# STM32MP13xx register map
File version: 1.5
CPU: CA7 r0p0, little endian, MPU, FPU, 4 interrupt priority bits
Registers are 32-bit, read-write, reset 0x0 unless marked. A register's access mark holds for its fields unless they carry their own. Offsets are from the block's base; [hi:lo] are bit positions; {n}, {i} and the like mark numbered series; 'fields as' and 'values as' point back to an identical list.

## ETH1 (part 4 of 4) — ETH
Base 0x5800A000
Same registers: ETH2 0x5800E000
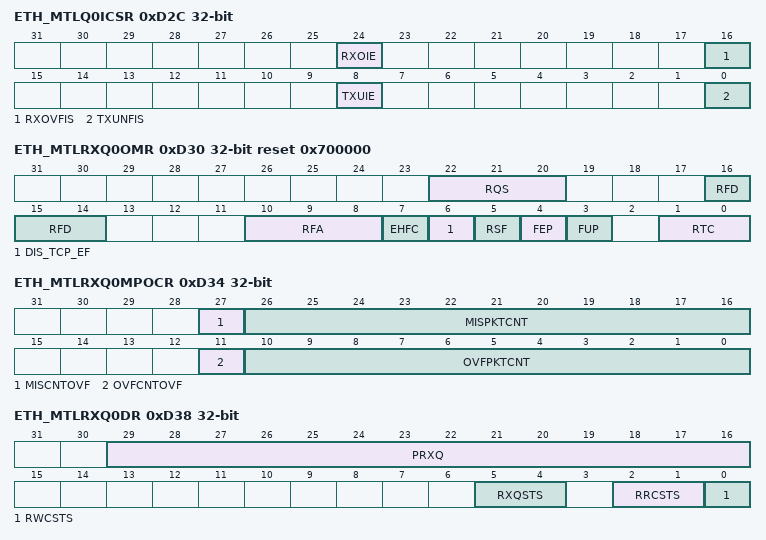
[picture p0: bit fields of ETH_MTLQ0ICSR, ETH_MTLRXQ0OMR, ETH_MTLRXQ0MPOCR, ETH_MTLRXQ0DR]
0xD2C ETH_MTLQ0ICSR — Queue 0 interrupt control status Register
  [24] RXOIE — Receive Queue Overflow Interrupt Enable When this bit is set, the Receive Queue Overflow interrupt is enabled. When this bit is reset, the Receive Queue Overflow interrupt is disabled.
  [16] RXOVFIS — Receive Queue Overflow Interrupt Status This bit indicates that the Receive Queue had an overflow while receiving the packet. If a partial packet is transferred to the application, the overflow status is set in RDES3[21]. This bit is cleared when the application writes 1 to this bit.
  [8] TXUIE — Transmit Queue Underflow Interrupt Enable When this bit is set, the Transmit Queue Underflow interrupt is enabled. When this bit is reset, the Transmit Queue Underflow interrupt is disabled.
  [0] TXUNFIS — Transmit Queue Underflow Interrupt Status This bit indicates that the Transmit Queue had an underflow while transmitting the packet. Transmission is suspended and an Underflow Error TDES3[2] is set. This bit is cleared when the application writes 1 to this bit.
0xD30 ETH_MTLRXQ0OMR access per field reset 0x700000 — Rx queue 0 operating mode register
  [22:20] RQS ro — Receive Queue Size This field indicates the size of the allocated Receive queues in blocks of 256 bytes. The RQS field is read-write only if the number of Rx queues more than one and the reset value is 0x0.
  [16:14] RFD rw — Threshold for Deactivating Flow Control (in half-duplex and full-duplex modes) These bits control the threshold (fill-level of Rx queue) at which the flow control is deasserted after activation: 2: Full minus 2 Kbytes, that is, FULL 2 Kbytes 3: Full minus 2.5 Kbytes, that is, FULL 2.5 Kbytes 4: Full minus 2.5 Kbytes, that is, FULL 3 Kbytes 5: Full minus 2.5 Kbytes, that is, FULL 3.5 Kbytes ... 6: Full minus 4 Kbytes, that is, FULL 4 Kbytes 7: Full minus 4.5 Kbytes, that is, FULL 4.5 Kbytes The deassertion is effective only after flow control is asserted. Note: The value must be programmed in such a way to make sure that the threshold is a positive number. When the EHFC is set high, these values are applicable only when the Rx queue size determined by the RQS field of this register, is equal to or greater than 4 Kbytes. For a given queue size, the values ranges between 0 and the encoding for FULL minus (QSIZE - 0.5 Kbyte) and all other values are illegal. Here the term FULL and QSIZE refers to the queue size determined by the RQS field of this register. The width of this field depends on RX FIFO size selected during the configuration. Remaining bits are reserved and read only. This field is reserved and read only when the RX FIFO size selected during configuration is less than 4Kbytes.
    0=Full minus 1 Kbyte, that is, FULL 1 Kbyte; 1=Full minus 1.5 Kbyte, that is, FULL 1.5 Kbyte
  [10:8] RFA rw — Threshold for Activating Flow Control (in half-duplex and full-duplex These bits control the threshold (fill-level of Rx queue) at which the flow control is activated: For more information on encoding for this field, see RFD.
  [7] EHFC rw — Enable Hardware Flow Control When this bit is set, the flow control signal operation, based on the fill-level of Rx queue, is enabled. When reset, the flow control operation is disabled. This bit is not used (reserved and always reset) when the Rx queue is less than 4 Kbytes.
  [6] DIS_TCP_EF rw — Disable Dropping of TCP/IP Checksum Error Packets When this bit is set, the MAC does not drop the packets which only have the errors detected by the Receive Checksum Offload engine. Such packets have errors only in the encapsulated payload. There are no errors (including FCS error) in the Ethernet packet received by the MAC. When this bit is reset, all error packets are dropped if the FEP bit is reset. This bit is reserved and RO when Enable Receive TCP/IP Checksum Check is not selected.
  [5] RSF rw — Receive Queue Store and Forward When this bit is set, the Ethernet peripheral reads a packet from the Rx queue only after the complete packet has been written to it, ignoring the RTC field of this register. When this bit is reset, the Rx queue operates in the Threshold (cut-through) mode, subject to the threshold specified by the RTC field of this register.
  [4] FEP rw — Forward Error Packets When this bit is reset, the Rx queue drops packets with error status (CRC error, receive error, watchdog timeout, or overflow). However, if the start byte (write) pointer of a packet is already transferred to the read controller side (in Threshold mode), the packet is not dropped. When this bit is set, all packets except the runt error packets are forwarded to the application or DMA. If the RSF bit is set and the Rx queue overflows when a partial packet is written, the packet is dropped irrespective of the setting of this bit. However, if the RSF bit is reset and the Rx queue overflows when a partial packet is written, a partial packet may be forwarded to the application or DMA.
  [3] FUP rw — Forward Undersized Good Packets When this bit is set, the Rx queue forwards the undersized good packets (packets with no error and length less than 64 bytes), including pad-bytes and CRC. When this bit is reset, the Rx queue drops all packets of less than 64 bytes, unless a packet is already transferred because of the lower value of Rx Threshold, for example, RTC = 01.
  [1:0] RTC rw — Receive Queue Threshold Control These bits control the threshold level of the MTL Rx queue (in bytes): The received packet is transferred to the application or DMA when the packet size within the MTL Rx queue is larger than the threshold. In addition, full packets with length less than the threshold are automatically transferred. This field is valid only when the RSF bit is zero. This field is ignored when the RSF bit is set to 1.
    0=64; 1=32; 2=96; 3=128
0xD34 ETH_MTLRXQ0MPOCR ro — Rx queue 0 missed packet and overflow counter register
  [27] MISCNTOVF — Missed Packet Counter Overflow Bit When set, this bit indicates that the Rx Queue Missed Packet Counter crossed the maximum limit.
  [26:16] MISPKTCNT — Missed Packet Counter This field indicates the number of packets missed by the Ethernet peripheral because the application asserted ari_pkt_flush_i[] for this queue. This counter is reset when this register is read. This counter is incremented by 1 when the DMA discards the packet because of buffer unavailability.
  [11] OVFCNTOVF — Overflow Counter Overflow Bit When set, this bit indicates that the Rx Queue Overflow Packet Counter field crossed the maximum limit.
  [10:0] OVFPKTCNT — Overflow Packet Counter This field indicates the number of packets discarded by the Ethernet peripheral because of Receive queue overflow. This counter is incremented each time the Ethernet peripheral discards an incoming packet because of overflow. This counter is reset when this register is read.
0xD38 ETH_MTLRXQ0DR ro — Rx queue 0 debug register
  [29:16] PRXQ — Number of Packets in Receive Queue This field indicates the current number of packets in the Rx queue. The theoretical maximum value for this field is 256Kbyte/16bytes = 16K Packets, that is, Max_Queue_Size/Min_Packet_Size.
  [5:4] RXQSTS — MTL Rx Queue Fill-Level Status This field gives the status of the fill-level of the Rx queue:
    0=Rx queue empty; 1=Rx queue fill-level below flow-control deactivate threshold; 2=Rx queue fill-level above flow-control activate threshold; 3=Rx queue full
  [2:1] RRCSTS — MTL Rx Queue Read Controller State This field gives the state of the Rx queue Read controller:
    0=Idle state; 1=Reading packet data; 2=Reading packet status (or timestamp); 3=Flushing the packet data and status
  [0] RWCSTS — MTL Rx Queue Write Controller Active Status When high, this bit indicates that the MTL Rx queue Write controller is active, and it is transferring a received packet to the Rx queue.
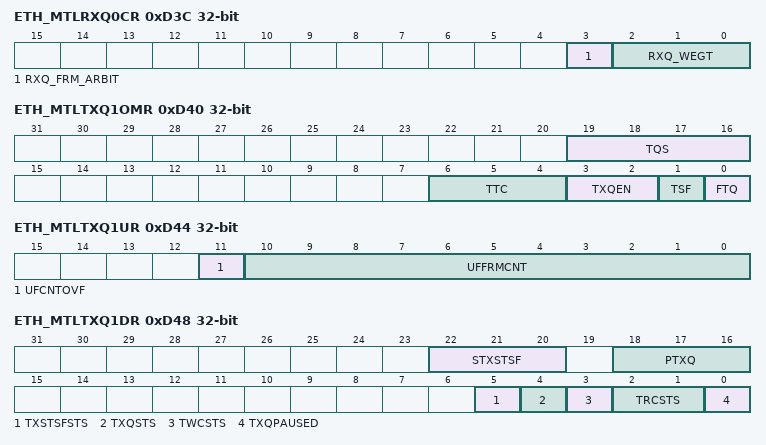
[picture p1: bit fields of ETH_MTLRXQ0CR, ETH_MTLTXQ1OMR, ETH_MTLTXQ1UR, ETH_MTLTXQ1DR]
0xD3C ETH_MTLRXQ0CR access per field — Rx queue 0 control register
  [3] RXQ_FRM_ARBIT ro — Receive Queue Packet Arbitration When this bit is set, the Ethernet peripheral drives the packet data to the ARI interface such that the entire packet data of currently-selected queue is transmitted before switching to other queue. When this bit is reset, the Ethernet peripheral drives the packet data to the ARI interface such that the following amount of data of currently-selected queue is transmitted before switching to other queue: PBL amount of data (indicated by ari_qN_pbl_i[]) or complete data of a packet The status and the timestamp are not a part of the PBL data. Therefore, the Ethernet peripheral drives the complete status (including timestamp status) during first PBL request for the packet (in store-and-forward mode) or the last PBL request for the packet (in Threshold mode).
  [2:0] RXQ_WEGT rw — Receive Queue Weight This field indicates the weight assigned to the Rx queue 0. The weight is used as the number of continuous PBL requests or contiguous packets (depending on the RXQ_PKT_ARBIT) allocated to the queue in one arbitration cycle.
0xD40 ETH_MTLTXQ1OMR — Tx queue 1 operating mode Register
  [19:16] TQS — Transmit queue size This field indicates the size of the allocated transmit queues in blocks of 256 bytes. Queue size range from 256 bytes (TQS=0b000) to 2048 bytes (TQS=0b111).
  [6:4] TTC — Transmit Threshold Control These bits control the threshold level of the MTL Tx queue. The transmission starts when the packet size within the MTL Tx queue is larger than the threshold. In addition, full packets with length less than the threshold are also transmitted. These bits are used only when the TSF bit is reset.
    0=32; 1=64; 2=96; 3=128; 4=192; 5=256; 6=384; 7=512
  [3:2] TXQEN — Transmit Queue Enable This field is used to enable/disable the transmit queue 0. Others: Reserved, must not be used. Note: In multiple Tx queues configuration, all the queues are disabled by default. Enable the Tx queue by programming this field.
    0=Not enabled; 2=Enabled
  [1] TSF — Transmit Store and Forward When this bit is set, the transmission starts when a full packet resides in the MTL Tx queue. When this bit is set, the TTC values specified in Bits[6:4] of this register are ignored. This bit should be changed only when the transmission is stopped.
  [0] FTQ — Flush Transmit Queue When this bit is set, the Tx queue controller logic is reset to its default values. Therefore, all the data in the Tx queue is lost or flushed. This bit is internally reset when the flushing operation is complete. Until this bit is reset, you should not write to the ETH_MTLTXQ1OMR register. The data which is already accepted by the MAC transmitter is not flushed. It is scheduled for transmission and results in underflow and runt packet transmission. Note: The flush operation is complete only when the Tx queue is empty and the application has accepted the pending Tx Status of all transmitted packets. To complete this flush operation, the PHY Tx clock (eth_mii_tx_clk) should be active.
0xD44 ETH_MTLTXQ1UR ro — Tx queue 1 underflow register
  [11] UFCNTOVF — Overflow Bit for Underflow Packet Counter This bit is set every time the Tx queue Underflow Packet Counter field overflows, that is, it has crossed the maximum count. In such a scenario, the overflow packet counter is reset to all-zeros and this bit indicates that the rollover happened.
  [10:0] UFFRMCNT — Underflow Packet Counter This field indicates the number of packets aborted by the controller because of Tx queue Underflow. This counter is incremented each time the MAC aborts outgoing packet because of underflow. The counter is cleared when this register is read.
0xD48 ETH_MTLTXQ1DR ro — Tx queue 1 debug Register
  [22:20] STXSTSF — Number of Status Words in Tx Status FIFO of Queue This field indicates the current number of status in the Tx Status FIFO of this queue. When the DTXSTS bit of ETH_MTLOMR register is set to 1, this field does not reflect the number of status words in Tx Status FIFO.
  [18:16] PTXQ — Number of Packets in the Transmit Queue This field indicates the current number of packets in the Tx queue. When the DTXSTS bit of ETH_MTLOMR register is set to 1, this field does not reflect the number of packets in the Transmit queue.
  [5] TXSTSFSTS — MTL Tx Status FIFO Full Status When high, this bit indicates that the MTL Tx Status FIFO is full. Therefore, the MTL cannot accept any more packets for transmission.
  [4] TXQSTS — MTL Tx Queue Not Empty Status When this bit is high, it indicates that the MTL Tx queue is not empty and some data is left for transmission.
  [3] TWCSTS — MTL Tx Queue Write Controller Status When high, this bit indicates that the MTL Tx queue Write Controller is active, and it is transferring the data to the Tx queue.
  [2:1] TRCSTS — MTL Tx Queue Read Controller Status This field indicates the state of the Tx Queue Read Controller:
    0=Idle state; 1=Read state (transferring data to the MAC transmitter); 2=Waiting for pending Tx Status from the MAC transmitter; 3=Flushing the Tx queue because of the Packet Abort request from the MAC
  [0] TXQPAUSED — Transmit Queue in Pause When this bit is high and the Rx flow control is enabled, it indicates that the Tx queue is in the Pause condition (in the full-duplex only mode) because of the following: Reception of the PFC packet for the priorities assigned to the Tx queue when PFC is enabled Reception of 802.3x Pause packet when PFC is disabled
0xD50 ETH_MTLTXQ1ECR — Tx queue 1 ETS control Register
  [3] CC — Credit Control When this bit is set, the accumulated credit parameter in the credit-based shaper algorithm logic is not reset to zero when there is positive credit and no packet to transmit in Channel 1. The credit accumulates even when there is no packet waiting in Channel 1 and another channel is transmitting. When this bit is reset, the accumulated credit parameter in the credit-based shaper algorithm logic is set to zero when there is positive credit and no packet to transmit in Channel 1. When there is no packet waiting in Channel 1 and other channel is transmitting, no credit is accumulated.
0xD54 ETH_MTLTXQ1ESR ro — Tx queue x ETS status Register
  [23:0] ABS — Average Bits per Slot This field contains the average transmitted bits per slot. When the DCB operation is enabled for Queue x, this field is computed over every 10 million bit times slot (10 ms in 1000 Mbps; 100 ms in 100 Mbps). The maximum value is 0x989680. This bit is reserved in configurations with only one transmit queue.
0xD58 ETH_MTLTXQ1QWR — Tx queue 1 quantum weight register
  [6:0] ISCQW — quantum weight If WRR algorithm is enabled for queue 1 generic traffic, this field contains the weight for this queue. The maximum value is 0x64.
0xD60 ETH_MTLTXQ1HCR — Tx Queue 1 hiCredit register
  [28:0] HC — hiCredit Value This field contains the hiCredit value required for the credit-based shaper algorithm. This is the maximum value that can be accumulated in the credit parameter. This is specified in bits scaled by 1 024. The maximum value is maxInterferenceSize, that is, best-effort maximum packet size (16 384 bytes or 131 072 bits). The value to be specified is 131 072 * 1 024 = 134 217 728 or 0x0800 0000.
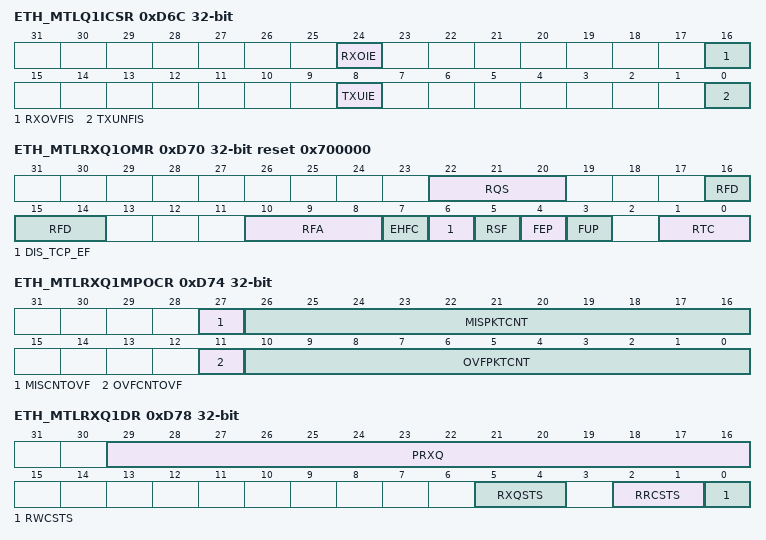
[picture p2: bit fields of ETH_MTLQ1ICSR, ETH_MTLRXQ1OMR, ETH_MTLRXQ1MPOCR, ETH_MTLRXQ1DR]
0xD6C ETH_MTLQ1ICSR — Queue 1 interrupt control status Register
  fields as ETH_MTLQ0ICSR
0xD70 ETH_MTLRXQ1OMR access per field reset 0x700000 — Rx queue 1 operating mode register
  fields as ETH_MTLRXQ0OMR
0xD74 ETH_MTLRXQ1MPOCR ro — Rx queue 1 missed packet and overflow counter register
  fields as ETH_MTLRXQ0MPOCR
0xD78 ETH_MTLRXQ1DR ro — Rx queue 1 debug register
  fields as ETH_MTLRXQ0DR
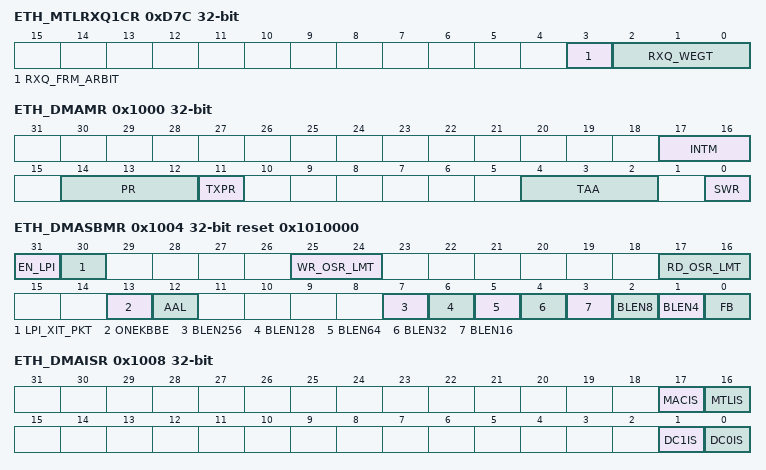
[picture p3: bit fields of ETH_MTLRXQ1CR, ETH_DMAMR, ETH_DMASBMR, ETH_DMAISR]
0xD7C ETH_MTLRXQ1CR access per field — Rx queue 1 control register
  fields as ETH_MTLRXQ0CR
0x1000 ETH_DMAMR access per field — DMA mode register
  [17:16] INTM rw — Interrupt Mode This field defines the interrupt mode of the Ethernet peripheral. The behavior of the interrupt signal and of the RI/TI bits in the ETH_DMACSR register changes depending on the INTM value (refer to behavior).
  [14:12] PR rw — Priority ratio These bits control the priority ratio in weighted round-robin arbitration between the Rx DMA and Tx DMA. These bits are valid only when the DA bit is reset. The priority ratio is Rx:Tx or Tx:Rx depending on whether the TXPR bit is reset or set.
    {v}=The priority ratio is {v+1}:1 (v=0..7)
  [11] TXPR rw — Transmit priority When set, this bit indicates that the Tx DMA has higher priority than the Rx DMA during arbitration for the system-side bus.
  [4:2] TAA ro — Transmit Arbitration Algorithm This field is used to select the arbitration algorithm for the Transmit side when multiple Tx DMAs are selected.
    0=Fixed priority. In fixed priority, Channel 0 has the lowest priority and the last channel has the highest priority.; 1=Weighted Strict Priority (WSP); 2=Weighted Round-Robin (WRR); {v}=Reserved, must not be used (v=3..7)
  [0] SWR rw — Software Reset When this bit is set, the MAC and the DMA controller reset the logic and all internal registers of the DMA, MTL, and MAC. This bit is automatically cleared after the reset operation is complete in all clock domains. Before reprogramming any register, a value of zero should be read in this bit. Note: The reset operation is complete only when all resets in all active clock domains are deasserted. Therefore, it is essential that all PHY inputs clocks (applicable for the selected PHY interface) are present for software reset completion. The time to complete the software reset operation depends on the frequency of the slowest active clock.
0x1004 ETH_DMASBMR reset 0x1010000 — System bus mode register
  [31] EN_LPI — Enable Low Power Interface (LPI) When set to 1, this bit enables the LPI mode and accepts the LPI request from the AXI System Clock controller. When set to 0, this bit disables the LPI mode and always denies the LPI request from the AXI System Clock controller.
  [30] LPI_XIT_PKT — Unlock on Magic Packet or Remote wakeup Packet When set to 1, this bit enables the AXI master to come out of the LPI mode only when the magic packet or remote wakeup packet is received. When set to 0, this bit enables the AXI master to come out of the LPI mode when any packet is received.
  [25:24] WR_OSR_LMT — AXI Maximum Write Outstanding Request Limit This value limits the maximum outstanding request on the AXI write interface. Maximum outstanding requests = WR_OSR_LMT + 1 Bit 27 is reserved Bit 26 is reserved
  [17:16] RD_OSR_LMT — AXI Maximum Read Outstanding Request Limit This value limits the maximum outstanding request on the AXI read interface. Maximum outstanding requests = RD_OSR_LMT + 1
  [13] ONEKBBE — 1 Kbyte Boundary Crossing Enable for the AXI Master When set, the burst transfers performed by the AXI master do not cross 1 Kbyte boundary. When reset, the burst transfers performed by the AXI master do not cross 4 Kbyte boundary.
  [12] AAL — Address-Aligned Beats When this bit is set to 1, the master performs address-aligned burst transfers on Read and Write channels.
  [7] BLEN256 — AXI Burst Length 256 When this bit is set to 1, the AXI master can select a burst length of 256 on the AXI interface.
  [6] BLEN128 — AXI Burst Length 128 When this bit is set to 1, the AXI master can select a burst length of 128 on the AXI interface.
  [5] BLEN64 — AXI Burst Length 64 When this bit is set to 1, the AXI master can select a burst length of 64 on the AXI interface.
  [4] BLEN32 — AXI Burst Length 32 When this bit is set to 1, the AXI master can select a burst length of 32 on the AXI interface.
  [3] BLEN16 — AXI Burst Length 16 When this bit is set to 1 or the FB bit is set to 0, the AXI master can select a burst length of 16 on the AXI interface. When the FB bit is set to 0, setting this bit has no effect.
  [2] BLEN8 — AXI Burst Length 8 When this bit is set to 1 or the FB bit is set to 0, the AXI master can select a burst length of 8 on the AXI interface. When the FB bit is set to 0, setting this bit has no effect.
  [1] BLEN4 — AXI Burst Length 4 When this bit is set to 1 or the FB bit is set to 0, the AXI master can select a burst length of 4 on the AXI interface. When the FB bit is set to 0, setting this bit has no effect.
  [0] FB — Fixed Burst Length When this bit is set to 1, the AXI master will initiate burst transfers of specified lengths as given below. Burst transfers of fixed burst lengths as indicated by the BLEN256, BLEN128, BLEN64, BLEN32, BLEN16, BLEN8, or BLEN4 field Burst transfers of length 1: when this bit is set to 0, the AXI master initiates burst transfers that are equal to or less than the maximum allowed burst length programmed in Bits[7:1].
0x1008 ETH_DMAISR ro — Interrupt status register
  [17] MACIS — MAC Interrupt Status This bit indicates an interrupt event in the MAC. To reset this bit to 1'b0, the software must read the corresponding register in the MAC to get the exact cause of the interrupt and clear its source.
  [16] MTLIS — MTL Interrupt Status This bit indicates an interrupt event in the MTL. To reset this bit to 1'b0, the software must read the corresponding register in the MTL to get the exact cause of the interrupt and clear its source.
  [1] DC1IS — DMA Channel 1 Interrupt Status This bit indicates an interrupt event in DMA Channel 1. To reset this bit to 0, the software must read the corresponding register in DMA Channel 1 to get the exact cause of the interrupt and clear its source.
  [0] DC0IS — DMA Channel 0 Interrupt Status This bit indicates an interrupt event in DMA Channel 0. To reset this bit to 0, the software must read the corresponding register in DMA Channel 0 to get the exact cause of the interrupt and clear its source.
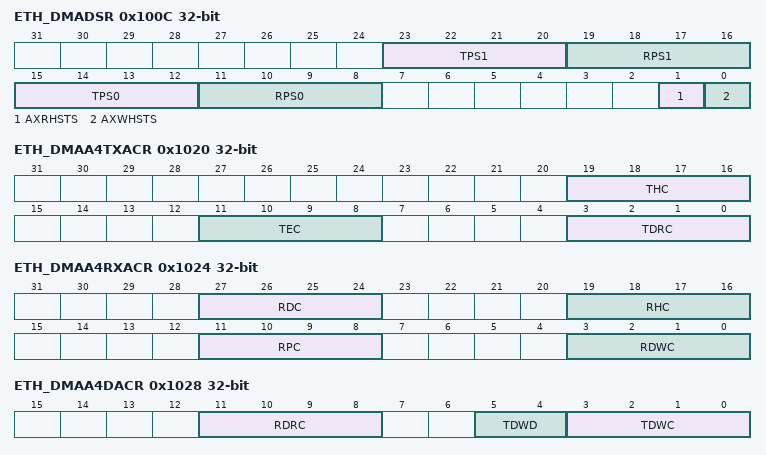
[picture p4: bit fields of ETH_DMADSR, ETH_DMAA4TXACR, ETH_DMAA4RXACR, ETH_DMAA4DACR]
0x100C ETH_DMADSR ro — Debug status register
  [23:20] TPS1 — DMA Channel 1 Transmit Process State This field indicates the Tx DMA FSM state for Channel 1. This field is similar to the TPS0 field.
  [19:16] RPS1 — DMA Channel 1 Receive Process State This field indicates the Rx DMA FSM state for Channel 1. This field is similar to the RPS0 field.
  [15:12] TPS0 — DMA Channel 0 Transmit Process State This field indicates the Tx DMA FSM state for Channel 0: The MSB of this field always returns 0. This field does not generate an interrupt.
    0=Stopped (Reset or Stop Transmit Command issued); 1=Running (Fetching Tx Transfer Descriptor); 2=Running (Waiting for status); 3=Running (Reading Data from system memory buffer and queuing it to the Tx buffer (Tx FIFO)); 4=Timestamp write state; 5=Reserved for future use; 6=Suspended (Tx Descriptor Unavailable or Tx Buffer Underflow); 7=Running (Closing Tx Descriptor)
  [11:8] RPS0 — DMA Channel 0 Receive Process State This field indicates the Rx DMA FSM state for Channel 0: The MSB of this field always returns 0. This field does not generate an interrupt.
    0=Stopped (Reset or Stop Receive Command issued); 1=Running (Fetching Rx Transfer Descriptor); 2=Reserved for future use; 3=Running (Waiting for Rx packet); 4=Suspended (Rx Descriptor Unavailable); 5=Running (Closing the Rx Descriptor); 6=Timestamp write state; 7=Running (Transferring the received packet data from the Rx buffer to the system memory)
  [1] AXRHSTS — AXI Master Read Channel Status When high, this bit indicates that the read channel of the AXI master is active, and it is transferring the data.
  [0] AXWHSTS — AXI Master Write Channel When high, this bit indicates that the write channel of the AXI master is active, and it is transferring data.
0x1020 ETH_DMAA4TXACR — AXI4 transmit channel ACE control register
  [19:16] THC — Transmit DMA First Packet Buffer or TSO Header Cache Control When TSO is NOT enabled, This field is used to drive arcache_o[3:0] signal when Transmit DMA is accessing First Buffer of the Packet (First valid buffer with FD being set in the TDES3 of the Descriptor). When TSO is enabled, This field is used to drive arcache_o[3:0] signal when the Transmit DMA is accessing the TSO Header data.
  [11:8] TEC — Transmit DMA Extended Packet Buffer or TSO Payload Cache Control When TSO is NOT enabled, This field is used to drive arcache o[3:0] signal when Transmit DMA is accessing the extended buffers (when packet is distributed across multiple buffers). When TSO is enabled, This field is used to drive arcache_o[3:0] signal when the Transmit DMA is accessing the TSO payload data.
  [3:0] TDRC — Transmit DMA Read Descriptor Cache Control This field is used to drive arcache_o[3:0] signal when Transmit DMA engines access the Descriptor.
0x1024 ETH_DMAA4RXACR — AXI4 receive channel ACE control register
  [27:24] RDC — Receive DMA Buffer Cache Control This field is used to drive awcache_o[3:0] signal when Receive DMA is accessing the Buffer when Header and payload are NOT separated.
  [19:16] RHC — Receive DMA Header Cache Control This field is used to drive awcache_o[3:0] and signal when Receive DMA is accessing the header Buffer when Header and payload are separated.
  [11:8] RPC — Receive DMA Payload Cache Control This field is used to drive awcache_o[3:0] signal when Receive DMA is accessing the Payload Buffer when Header and payload are separated.
  [3:0] RDWC — Receive DMA Write Descriptor Cache Control This field is used to drive awcache_o[3:0] signal when Receive DMA accesses the Descriptor.
0x1028 ETH_DMAA4DACR — AXI4 descriptor ACE control register
  [11:8] RDRC — Receive DMA Read Descriptor Cache control This field is used to drive arcache_o[3:0] signal when Receive DMA engines read the Descriptor.
  [5:4] TDWD — Transmit DMA Write Descriptor Domain control This field is used to drive awdomain_o[1:0] signal when Transmit DMA write to the Descriptor.
  [3:0] TDWC — Transmit DMA Write Descriptor Cache control This field is used to drive awcache_o[3:0] signal when Transmit DMA writes to the Descriptor.
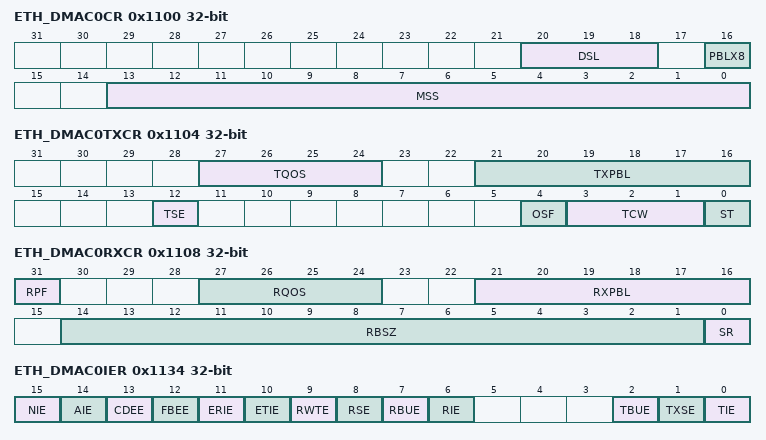
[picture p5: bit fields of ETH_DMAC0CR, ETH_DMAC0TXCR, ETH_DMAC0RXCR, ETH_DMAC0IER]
0x1100 ETH_DMAC0CR — Channel 0 control register
  [20:18] DSL — Descriptor Skip Length This bit specifies the 32-bit word number to skip between two unchained descriptors. The address skipping starts from the end of the current descriptor to the start of the next descriptor. When the DSL value is equal to zero, the DMA takes the descriptor table as contiguous.
  [16] PBLX8 — 8xPBL mode When this bit is set, the PBL value programmed in Bits[21:16] in ETH_DMACiTXCR is multiplied eight times. Therefore, the DMA transfers the data in 8, 16, 32, 64, 128, and 256 beats depending on the PBL value.
  [13:0] MSS — Maximum Segment Size This field specifies the maximum segment size that should be used while segmenting the packet. This field is valid only if the TSE bit of ETH_DMACiTXCR register is set. The value programmed in this field must be more than the configured Data width in bytes. It is recommended to use a MSS value of 64 bytes or more.
0x1104 ETH_DMAC0TXCR access per field — Channel 0 transmit control register
  [27:24] TQOS rw — Transmit QOS. This field is used to drive arqos_m_o[3:0] or awqos_m_o[3:0] output signals for all transactions of DMA Tx Channel i.
  [21:16] TXPBL rw — Transmit Programmable Burst Length These bits indicate the maximum number of beats to be transferred in one DMA data transfer. This is the maximum value that is used in a single block Read or Write. The DMA always attempts to burst as specified in PBL each time it starts a burst transfer on the application bus. You can program PBL with any of the following values: 1, 2, 4, 8, 16, or 32. Any other value results in undefined behavior. To transfer more than 32 beats, perform the following steps: 1. Set the PBLx8 mode in ETH_DMACiCR. 2. Set the PBL.
  [12] TSE rw — TCP Segmentation Enabled When this bit is set, the DMA performs the TCP segmentation for packets in Channel i. The TCP segmentation is done only for those packets for which the TSE bit (TDES0[19]) is set in the Tx Normal descriptor. When this bit is set, the TxPBL value must be greater than or equal to 4.
  [4] OSF rw — Operate on Second Packet When this bit is set, it instructs the DMA to process the second packet of the Transmit data even before the status for the first packet is obtained.
  [3:1] TCW ro — Transmit Channel Weight This field indicates the weight assigned to the corresponding Transmit channel. When reset is complete, this field is set to 0 for all channels by default, resulting in equal weights to all channels.
  [0] ST rw — Start or Stop Transmission Command When this bit is set, transmission is placed in the Running state. The DMA checks the Transmit list at the current position for a packet to be transmitted. The DMA tries to acquire descriptor from either of the following positions: The current position in the list: this is the base address of the Transmit list set by the ETH_DMACiTXDLAR register. The position at which the transmission was previously stopped If the DMA does not own the current descriptor, the transmission enters the Suspended state and the TBU bit of the ETH_DMACiSR is set. The Start Transmission command is effective only when the transmission is stopped. If the command is issued before setting the ETH_DMACiTXDLAR register, the DMA behavior is unpredictable. When this bit is reset, the transmission process is placed in the Stopped state after completing the transmission of the current packet. The Next Descriptor position in the Transmit list is saved, and it becomes the current position when the transmission is restarted. To change the list address, you need to program ETH_DMACiTXDLAR register with a new value when this bit is reset. The new value is considered when this bit is set again. The stop transmission command is effective only when the transmission of the current packet is complete or the transmission is in the Suspended state.
0x1108 ETH_DMAC0RXCR — Channel 0 receive control register
  [31] RPF — DMA Rx Channel0 Packet Flush When this bit is set to 1, the DMA will automatically flush the packet from the Rx queues destined to DMA Rx Channel 0 when the DMA Rx Channel 0 is stopped after a system bus error has occurred. The flushing happens on the Read side of the Rx queue. When this bit is set to 0 the EQOS will not flush the packet in the Rx queue destined to DMA Rx Channel 0 after the DMA is stopped due to a system bus error.
  [27:24] RQOS — Rx AXI4 QOS. This field is used to drive arqos_m_o[3:0] or awqos_m_o[3:0] output signals for all transactions of DMA Rx Channel0.
  [21:16] RXPBL — Receive Programmable Burst Length These bits indicate the maximum number of beats to be transferred in one DMA data transfer. This is the maximum value that is used in a single block Read or Write. The DMA always attempts to burst as specified in PBL each time it starts a burst transfer on the application bus. You can program PBL with any of the following values: 1, 2, 4, 8, 16, or 32. Any other value results in undefined behavior. To transfer more than 32 beats, perform the following steps: 1. Set the PBLx8 mode in the ETH_DMAC0CR. 2. Set the PBL.
  [14:1] RBSZ — Receive Buffer size This field indicates the size of the Rx buffers specified in bytes. The maximum buffer size is limited to 16 Kbytes. The buffer size is applicable to payload buffers when split headers are enabled. Note: The buffer size must be a multiple of 4, 8, or 16 depending on the bus widths (32, 64, or 128 respectively). This is required even if the value of buffer address pointer is not aligned to bus width. If the buffer size is not a multiple of 4, 8, or 16, it may result into undefined behavior. The LSB bits (1:0, 2:0, or 3:0) for 32-bit, 64-bit, or 128-bit bus width are ignored and the DMA internally takes the LSB bits as all-zero. Therefore, these LSB bits are read-only (RO).
  [0] SR — Start or Stop Receive When this bit is set, the DMA tries to acquire the descriptor from the Receive list and processes the incoming packets. The DMA tries to acquire descriptor from either of the following positions: The current position in the list: this is the address set by the ETH_DMAC0RXDLAR register. The position at which the Rx process was previously stopped If the DMA does not own the current descriptor, the reception is suspended and the RBU bit of the ETH_DMAC0SR is set. The Start Receive command is effective only when the reception is stopped. If the command is issued before setting the ETH_DMAC0RXDLAR register, the DMA behavior is unpredictable. When this bit is reset, the Rx DMA operation is stopped after the transfer of the current packet. The next descriptor position in the Receive list is saved, and it becomes the current position after the Rx process is restarted. The Stop Receive command is effective only when the Rx process is in the Running (waiting for Rx packet) or Suspended state.
0x1114 ETH_DMAC0TXDLAR — Channel 0 Tx descriptor list address register
  [31:2] TDESLA — Start of Transmit List This field contains the base address of the first descriptor in the Transmit descriptor list. The DMA ignores the LSB bits (1:0, 2:0, or 3:0) for 32-bit bus width and internally takes these bits as all-zero. Therefore, these LSB bits are read-only (RO). The width of this field depends on the configuration: 31:2 for 32-bit configuration
0x111C ETH_DMAC0RXDLAR — Channel 0 Rx descriptor list address register
  [31:2] RDESLA — Start of Receive List This field contains the base address of the first descriptor in the Rx Descriptor list. The DMA ignores the LSB bits (1:0, 2:0, or 3:0) for 32-bit bus width and internally takes these bits as all-zero. Therefore, these LSB bits are read-only (RO). The width of this field depends on the configuration: 31:2 for 32-bit configuration
0x1120 ETH_DMAC0TXDTPR — Channel 0 Tx descriptor tail pointer register
  [31:2] TDT — Transmit Descriptor Tail Pointer This field contains the tail pointer for the Tx descriptor ring. The software writes the tail pointer to add more descriptors to the Tx channel. The hardware tries to transmit all packets referenced by the descriptors between the head and the tail pointer registers. The width of this field depends on the configuration: 31:2 for 32-bit configuration
0x1128 ETH_DMAC0RXDTPR — Channel 0 Rx descriptor tail pointer register
  [31:2] RDT — Receive Descriptor Tail Pointer This field contains the tail pointer for the Rx descriptor ring. The software writes the tail pointer to add more descriptors to the Rx channel. The hardware tries to write all received packets to the descriptors referenced between the head and the tail pointer registers. The width of this field depends on the configuration: 31:2 for 32-bit configuration
0x112C ETH_DMAC0TXRLR — Channel 0 Tx descriptor ring length register
  [9:0] TDRL — Transmit Descriptor Ring Length This field sets the maximum number of Tx descriptors in the circular descriptor ring. The maximum number of descriptors is limited to 1K descriptors. It is recommended to put a minimum ring descriptor length of 4.
0x1130 ETH_DMAC0RXRLR — Channel 0 Rx descriptor ring length register
  [9:0] RDRL — Receive Descriptor Ring Length This register sets the maximum number of Rx descriptors in the circular descriptor ring. The maximum number of descriptors is limited to 1K descriptors.
0x1134 ETH_DMAC0IER — Channel 0 interrupt enable register
  [15] NIE — Normal Interrupt Summary Enable When this bit is set, the normal interrupt summary is enabled. This bit enables the following interrupts in the ETH_DMAC0SR: Bit 0: Transmit Interrupt Bit 2: Transmit Buffer Unavailable Bit 6: Receive Interrupt Bit 11: Early Receive Interrupt When this bit is reset, the normal interrupt summary is disabled.
  [14] AIE — Abnormal Interrupt Summary Enable When this bit is set, the abnormal interrupt summary is enabled. This bit enables the following interrupts in the ETH_DMAC0SR: Bit 1: Transmit Process Stopped Bit 7: Rx Buffer Unavailable Bit 8: Receive Process Stopped Bit 9: Receive Watchdog Timeout Bit 10: Early Transmit Interrupt Bit 12: Fatal Bus Error When this bit is reset, the abnormal interrupt summary is disabled.
  [13] CDEE — Context Descriptor Error Enable When this bit is set along with the AIE bit, the Context Descriptor error interrupt is enabled. When this bit is reset, the Context Descriptor error interrupt is disabled.
  [12] FBEE — Fatal Bus Error Enable When this bit is set along with the AIE bit, the Fatal Bus error interrupt is enabled. When this bit is reset, the Fatal Bus Error error interrupt is disabled.
  [11] ERIE — Early Receive Interrupt Enable When this bit is set along with the NIE bit, the Early Receive interrupt is enabled. When this bit is reset, the Early Receive interrupt is disabled.
  [10] ETIE — Early Transmit Interrupt Enable When this bit is set along with the AIE bit, the Early Transmit interrupt is enabled. When this bit is reset, the Early Transmit interrupt is disabled.
  [9] RWTE — Receive Watchdog Timeout Enable When this bit is set along with the AIE bit, the Receive Watchdog Timeout interrupt is enabled. When this bit is reset, the Receive Watchdog Timeout interrupt is disabled.
  [8] RSE — Receive Stopped Enable When this bit is set along with the AIE bit, the Receive Stopped Interrupt is enabled. When this bit is reset, the Receive Stopped interrupt is disabled.
  [7] RBUE — Receive Buffer Unavailable Enable When this bit is set along with the AIE bit, the Receive Buffer Unavailable interrupt is enabled. When this bit is reset, the Receive Buffer Unavailable interrupt is disabled.
  [6] RIE — Receive Interrupt Enable When this bit is set along with the NIE bit, the Receive Interrupt is enabled. When this bit is reset, the Receive Interrupt is disabled.
  [2] TBUE — Transmit Buffer Unavailable Enable When this bit is set along with the NIE bit, the Transmit Buffer Unavailable interrupt is enabled. When this bit is reset, the Transmit Buffer Unavailable interrupt is disabled.
  [1] TXSE — Transmit Stopped Enable When this bit is set along with the AIE bit, the Transmission Stopped interrupt is enabled. When this bit is reset, the Transmission Stopped interrupt is disabled.
  [0] TIE — Transmit Interrupt Enable When this bit is set along with the NIE bit, the Transmit Interrupt is enabled. When this bit is reset, the Transmit Interrupt is disabled.
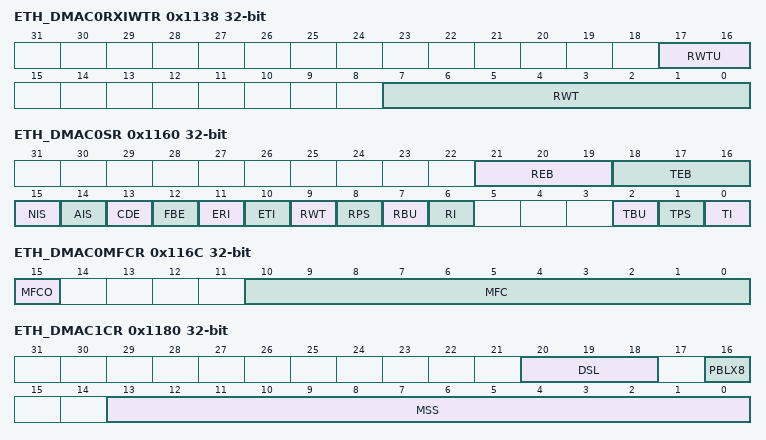
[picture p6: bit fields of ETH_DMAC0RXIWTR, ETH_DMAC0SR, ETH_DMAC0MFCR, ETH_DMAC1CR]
0x1138 ETH_DMAC0RXIWTR — Channel 0 Rx interrupt watchdog timer register
  [17:16] RWTU — Receive Interrupt Watchdog Timer Count Units This field indicates the number of system clock cycles corresponding to one unit in RWT[7:0] field. For example, when RWT[7:0] = 2 and RWTU[1:0] = 1, the watchdog timer is set for 2 * 512 = 1024 system clock cycles.
    0=256; 1=512; 2=1024; 3=2048
  [7:0] RWT — Receive Interrupt Watchdog Timer Count This field indicates the number of system clock cycles, multiplied by factor indicated in RWTU field, for which the watchdog timer is set. The watchdog timer is triggered with the programmed value after the Rx DMA completes the transfer of a packet for which the RI bit is not set in the ETH_DMAC0SR, because of the setting of Interrupt Enable bit in the corresponding descriptor RDES3[30]. When the watchdog timer runs out, the RI bit is set and the timer is stopped. The watchdog timer is reset when the RI bit is set high because of automatic setting of RI as per the Interrupt Enable bit RDES3[30] of any received packet.
0x1144 ETH_DMAC0CATXDR ro — Channel 0 current application transmit descriptor register
  [31:0] CURTDESAPTR — Application Transmit Descriptor Address Pointer The DMA updates this pointer during Tx operation. This pointer is cleared on reset.
0x114C ETH_DMAC0CARXDR ro — Channel 0 current application receive descriptor register
  [31:0] CURRDESAPTR — Application Receive Descriptor Address Pointer The DMA updates this pointer during Rx operation. This pointer is cleared on reset.
0x1154 ETH_DMAC0CATXBR ro — Channel 0 current application transmit buffer register
  [31:0] CURTBUFAPTR — Application Transmit Buffer Address Pointer The DMA updates this pointer during Tx operation. This pointer is cleared on reset.
0x115C ETH_DMAC0CARXBR ro — Channel 0 current application receive buffer register
  [31:0] CURRBUFAPTR — Application Receive Buffer Address Pointer The DMA updates this pointer during Rx operation. This pointer is cleared on reset.
0x1160 ETH_DMAC0SR access per field — Channel 0 status register
  [21:19] REB ro — Rx DMA Error Bits This field indicates the type of error that caused a Bus Error. For example, error response on the AXI interface. Bit [2]: Error during data transfer by Rx DMA when '1', no when '0' Bit[1]: Error during descriptor access when '1', Error during data buffer access when '0' Bit[0]: Error during read transfer when '1', Error during write transfer when '0' This field is valid only when the FBE bit is set. This field does not generate an interrupt.
  [18:16] TEB ro — Tx DMA Error Bits This field indicates the type of error that caused a Bus Error. For example, error response on the AXI interface. Bit[2]: Error during data transfer by Tx DMA when '1', no when '0' Bit[1]: Error during descriptor access when '1', Error during data buffer access when '0' Bit[0]: Error during read transfer when '1', Error during write transfer when '0' This field is valid only when the FBE bit is set. This field does not generate an interrupt.
  [15] NIS rw — Normal Interrupt Summary Normal Interrupt Summary bit value is the logical OR of the following bits when the corresponding interrupt bits are enabled in the ETH_DMACiIER register: Bit 0: Transmit Interrupt Bit 2: Transmit Buffer Unavailable Bit 6: Receive Interrupt Bit 11: Early Receive Interrupt Only unmasked bits (interrupts for which interrupt enable is set in ETH_DMACiIER register) affect the Normal Interrupt Summary bit. This is a sticky bit. You must clear this bit (by writing 1 to this bit) each time a corresponding bit which causes NIS to be set is cleared.
  [14] AIS rw — Abnormal Interrupt Summary Abnormal Interrupt Summary bit value is the logical OR of the following when the corresponding interrupt bits are enabled in the ETH_DMACiIER register: Bit 1: Transmit Process Stopped Bit 7: Receive Buffer Unavailable Bit 8: Receive Process Stopped Bit 10: Early Transmit Interrupt Bit 12: Fatal Bus Error Bit 13: Context Descriptor Error Only unmasked bits affect the Abnormal Interrupt Summary bit. This is a sticky bit. You must clear this bit (by writing 1 to this bit) each time a corresponding bit, which causes AIS to be set, is cleared.
  [13] CDE rw — Context Descriptor Error This bit indicates that the DMA Tx engine received a context descriptor in the middle of a packet (in an intermediate descriptor), and the DMA Tx engine ignored it.
  [12] FBE rw — Fatal Bus Error This bit indicates that a bus error occurred (as described in the EB field). When this bit is set, the corresponding DMA channel engine disables all bus accesses.
  [11] ERI rw — Early Receive Interrupt This bit indicates that the DMA filled the first data buffer of the packet. The RI bit of this register automatically clears this bit.
  [10] ETI rw — Early Transmit Interrupt This bit indicates that the packet to be transmitted is fully transferred to the MTL Tx FIFO.
  [9] RWT rw — Receive Watchdog Timeout This bit is asserted when a packet with length greater than 2,048 bytes (10,240 bytes when Jumbo Packet mode is enabled) is received.
  [8] RPS rw — Receive Process Stopped This bit is asserted when the Rx process enters the Stopped state.
  [7] RBU rw — Receive Buffer Unavailable This bit indicates that the application owns the next descriptor in the Receive list, and the DMA cannot acquire it. The Rx process is suspended. To resume processing Rx descriptors, the application should change the ownership of the descriptor and issue a Receive Poll Demand command. If this command is not issued, the Rx process resumes when the next recognized incoming packet is received. In ring mode, the application should advance the Receive Descriptor Tail Pointer register of a channel. This bit is set only when the DMA owns the previous Rx descriptor.
  [6] RI rw — Receive Interrupt This bit indicates that the packet reception is complete. When packet reception is complete, Bit 31 of RDES1 is reset in the last descriptor, and the specific packet status information is updated in the descriptor. The reception remains in the Running state.
  [2] TBU rw — Transmit Buffer Unavailable This bit indicates that the application owns the next descriptor in the Transmit list, and the DMA cannot acquire it. Transmission is suspended. The TPS0 field of the DMA_Debug_Status0 register explains the Transmit Process state transitions. To resume processing the Transmit descriptors, the application should do the following: 1. Change the ownership of the descriptor by setting Bit 31 of TDES3. 2. Issue a Transmit Poll Demand command. For ring mode, the application should advance the Transmit Descriptor Tail Pointer register of a channel.
  [1] TPS rw — Transmit Process Stopped This bit is set when the transmission is stopped.
  [0] TI rw — Transmit Interrupt This bit indicates that the packet transmission is complete. When transmission is complete, Bit 31 of TDES3 is reset in the last descriptor, and the specific packet status information is updated in the descriptor.
0x116C ETH_DMAC0MFCR ro — Channel 0 missed frame count register
  [15] MFCO — Overflow status of the MFC Counter When this bit is set then the MFC counter does not get incremented further. The bit gets cleared when this register is read.
  [10:0] MFC — Dropped Packet Counters This counter indicates the number of packet counters that are dropped by the DMA either because of bus error or because of programing RPF field in ETH_DMAC0RXCR register. The counter gets cleared when this register is read.
0x1180 ETH_DMAC1CR — Channel 1 control register
  fields as ETH_DMAC0CR
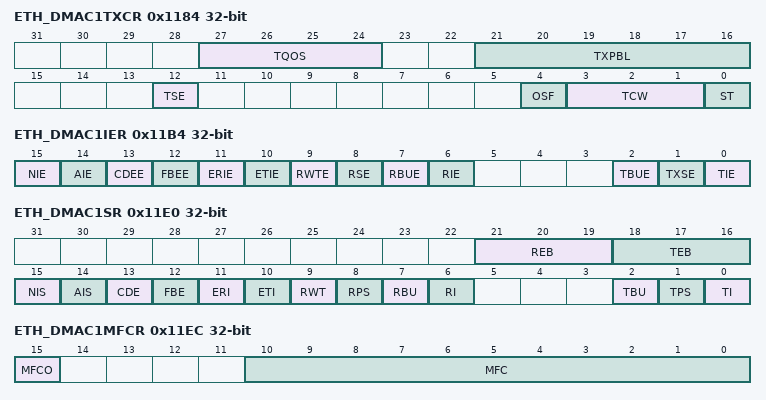
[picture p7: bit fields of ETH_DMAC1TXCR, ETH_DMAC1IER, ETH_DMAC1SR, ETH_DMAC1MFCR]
0x1184 ETH_DMAC1TXCR access per field — Channel 1 transmit control register
  fields as ETH_DMAC0TXCR
0x1194 ETH_DMAC1TXDLAR — Channel 1 Tx descriptor list address register
  fields as ETH_DMAC0TXDLAR
0x11A0 ETH_DMAC1TXDTPR — Channel 1 Tx descriptor tail pointer register
  fields as ETH_DMAC0TXDTPR
0x11AC ETH_DMAC1TXRLR — Channel 1 Tx descriptor ring length register
  fields as ETH_DMAC0TXRLR
0x11B4 ETH_DMAC1IER — Channel 1 interrupt enable register
  fields as ETH_DMAC0IER
0x11C4 ETH_DMAC1CATXDR ro — Channel 1 current application transmit descriptor register
  fields as ETH_DMAC0CATXDR
0x11D4 ETH_DMAC1CATXBR ro — Channel 1 current application transmit buffer register
  fields as ETH_DMAC0CATXBR
0x11E0 ETH_DMAC1SR access per field — Channel 1 status register
  fields as ETH_DMAC0SR
0x11EC ETH_DMAC1MFCR ro — Channel 1 missed frame count register
  fields as ETH_DMAC0MFCR
